# USB0_VBP2AHB_WRAP_CONTROLLER_VBP_USB3_CORE_DB register map
Vendor: Texas Instruments
Peripheral module from a debugger description file (folder am62P).
Registers are 32-bit, read-write, reset 0x0 unless marked. A register's access mark holds for its fields unless they carry their own. Offsets are as the file gives them; lines under a group give offsets from that group; [hi:lo] are bit positions; {n}, {i} and the like mark numbered series; 'fields as' and 'values as' point back to an identical list; <NAME> marks a mode.

## USB0_VBP2AHB_WRAP_CONTROLLER_VBP_USB3_CORE_DB
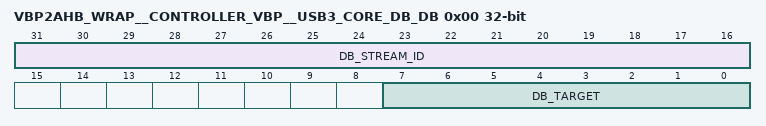
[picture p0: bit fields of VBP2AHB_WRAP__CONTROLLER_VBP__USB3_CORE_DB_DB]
0x00 VBP2AHB_WRAP__CONTROLLER_VBP__USB3_CORE_DB_DB — Doorbell Register Bit Field Definitions For a description of this standard USB register field, see the eXtensible Host Controller Interface for Universal Serial Bus (USB) Specification 3.0. Programming this field with random data will cause side effect i.e. Register Access will fail (Timeout) if the pipe clock is not running or reset is asserted . Bit Bash register testing is not recommended.
  [31:16] DB_STREAM_ID — DB_STREAM_ID For a description of this standard USB register field, see the eXtensible Host Controller Interface for Universal Serial Bus [USB] Specification 3.0.
  [7:0] DB_TARGET — DB_TARGET For a description of this standard USB register field, see the eXtensible Host Controller Interface for Universal Serial Bus [USB] Specification 3.0.
